# M368 register map
File version: 0.1
TOSHIBA Cortex-M3 MCU
Registers are 32-bit, read-write, reset 0x0 unless marked. A register's access mark holds for its fields unless they carry their own. Offsets are from the block's base; lines under a group give offsets from that group; [hi:lo] are bit positions; {n}, {i} and the like mark numbered series; 'fields as' and 'values as' point back to an identical list; <NAME> marks a mode.

## Memory map
0x40005000 CANMB0 blocks up to offset 0x1C — CAN Controller (TXCAN) Mailbox RAM
{0x40005000+0x20*n} CANMB{n} blocks up to offset 0x1C (n=1..30)
0x400053E0 CANMB31 blocks up to offset 0x1C — CAN Controller (TXCAN) Mailbox RAM
0x40005400 CAN blocks up to offset 0xBC — CAN Controller (TXCAN)
0x40006000 HC blocks up to offset 0x84 — USB Host Controller (USBHC)
0x40008000 UDFS blocks up to offset 0x8C — UDC2 AHB Bridge
0x40008200 UDFS2 blocks up to offset 0x338 — UDC2(USB -Spec2.0 Device contoller)
0x40040000 SSP0 size 0x28 — Synchronous Serial Port
0x40041000 SSP1 size 0x28
0x40042000 SSP2 size 0x28
0x40048000 UART4 blocks up to offset 0x4C — ARM Prime Cell PL011
0x40049000 UART5 blocks up to offset 0x4C
0x4004C000 DMAA blocks up to offset 0x50 — DMA Controller
0x4004D000 DMAB blocks up to offset 0x50
0x40050000 ADA blocks up to offset 0x78 — Analog-to-Digital Converter (AD)
0x40051000 ADB blocks up to offset 0x78 — Analog-to-Digital Converter (AD)
0x40052000 ADILV size 0xC — Dual ADC Configuration
0x40054000 DA0 size 0x14 — Digital-to-Analog Converter (DA)
0x40055000 DA1 size 0x14
0x4005C000 EXB blocks up to offset 0x50 — External Bus Interface(EXB)
0x400C0000 PA blocks up to offset 0x3C — General Purpose Input_Output Port (PA)
0x400C0100 PB blocks up to offset 0x3C — General Purpose Input_Output Port (PB)
0x400C0400 PE blocks up to offset 0x3C — General Purpose Input_Output Port (PE)
0x400C0500 PF blocks up to offset 0x3C — General Purpose Input_Output Port (PF)
0x400C0600 PG blocks up to offset 0x3C — General Purpose Input_Output Port (PG)
0x400C0700 PH blocks up to offset 0x3C — General Purpose Input_Output Port (PH)
0x400C0800 PI blocks up to offset 0x3C — General Purpose Input_Output Port (PI)
0x400C0A00 PK blocks up to offset 0x3C — General Purpose Input_Output Port (PK)
0x400C0B00 PL blocks up to offset 0x3C — General Purpose Input_Output Port (PL)
0x400C4000 TB0 size 0x34 — 16-bit Timer_Event Counter (TB)
0x400C4100 TB1 size 0x34
0x400C4200 TB2 size 0x34
0x400C4300 TB3 size 0x34
0x400C4400 TB4 size 0x34
0x400C4500 TB5 size 0x34
0x400C4600 TB6 size 0x34
0x400C4700 TB7 size 0x34
0x400C7000 MT0 size 0x58 — 16-bit Multi-Purpose Timer (MPT-TMR_IGBT)
0x400C7100 MT1 size 0x58
0x400C7200 MT2 size 0x58
0x400C7300 MT3 size 0x58
0x400CC000 RTC blocks up to offset 0xD — Real Time Clock (RTC)
0x400E0000 SBI0 size 0x18 — Serial Bus Interface (SBI)
0x400E0100 SBI1 size 0x18
0x400E0200 SBI2 size 0x18
0x400E1000 SC0 size 0x34 — Serial Channel (SC)
0x400E1100 SC1 size 0x34
0x400E1200 SC2 size 0x34
0x400E1300 SC3 size 0x34
0x400E7000 RMC size 0x38 — Remote Control Signal Preprocessor (RMC)
0x400F1000 OFD size 0x24 — Oscillation Frequency Detector (OFD)
0x400F2000 WD size 0x8 — Watchdog Timer (WD)
0x400F3000 CG blocks up to offset 0x6C — Clock Generator (CG)
0x400F3100 USBPLL size 0xC — Low Voltage detector control register
0x400F3200 TRMOSC size 0x10 — Low Voltage detector control register
0x400F4000 LVD size 0xC — Low Voltage detector control register
0x400F6000 MTPD blocks up to offset 0x48 — 16-bit Multi-Purpose Timer (MPT-PMD)
0x400F7000 EN size 0x10 — Encoder Input (ENC)
0x41FFF000 FC blocks up to offset 0x24 — Flash Control (FC)

## CANMB0 — CAN Controller (TXCAN) Mailbox RAM
Base 0x40005000
Same registers: CANMB{n} {0x40005000+0x20*n} (n=1..30)
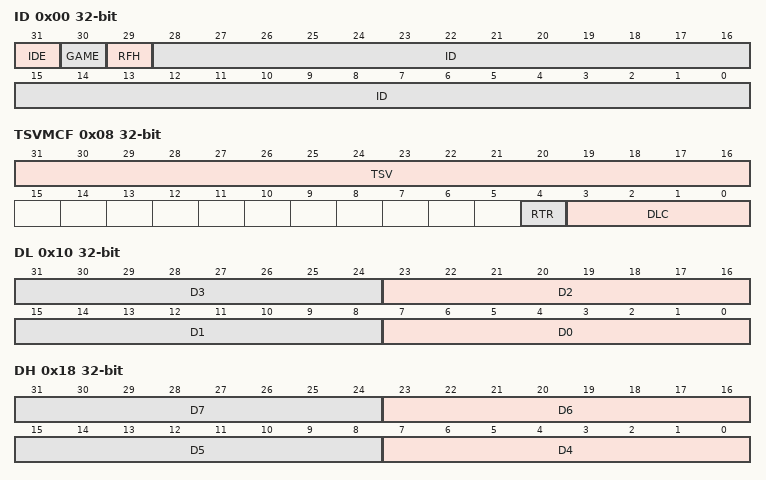
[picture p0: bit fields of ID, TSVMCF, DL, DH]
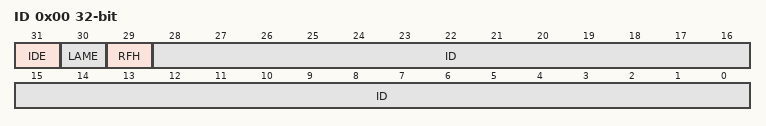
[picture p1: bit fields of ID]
0x00 ID reset not defined — CAN Mailbox Register
  [31] IDE, [30] GAME, [29] RFH, [28:0] ID
0x08 TSVMCF reset not defined — CAN Mailbox Register
  [31:16] TSV, [4] RTR, [3:0] DLC
0x10 DL reset not defined — CAN Mailbox Register
  [8n+7:8n] D{n} (n=0..3)
0x18 DH reset not defined — CAN Mailbox Register
  [8n-25:8n-32] D{n} (n=4..7)

## CANMB31 — CAN Controller (TXCAN) Mailbox RAM
Base 0x400053E0
Registers as CANMB0; these are added or differ:
0x00 ID reset not defined — CAN Mailbox Register
  [31] IDE, [30] LAME, [29] RFH, [28:0] ID
